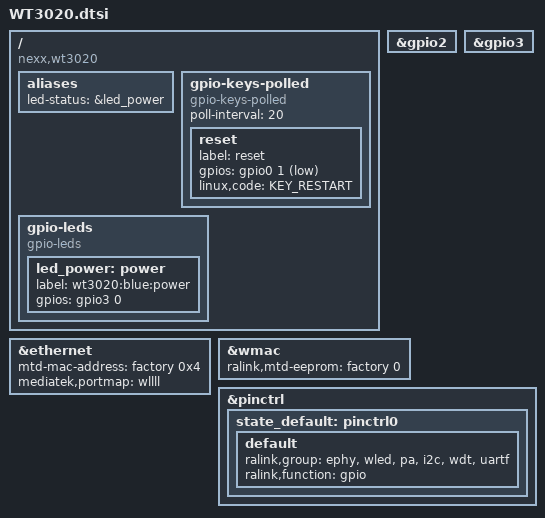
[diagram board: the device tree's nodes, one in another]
#include "mt7620n.dtsi"

#include <dt-bindings/gpio/gpio.h>
#include <dt-bindings/input/input.h>

/ {
	compatible = "nexx,wt3020", "ralink,mt7620n-soc";

	aliases {
		led-status = &led_power;
	};

	gpio-keys-polled {
		compatible = "gpio-keys-polled";
		poll-interval = <20>;

		reset {
			label = "reset";
			gpios = <&gpio0 1 GPIO_ACTIVE_LOW>;
			linux,code = <KEY_RESTART>;
		};
	};

	gpio-leds {
		compatible = "gpio-leds";

		led_power: power {
			label = "wt3020:blue:power";
			gpios = <&gpio3 0 GPIO_ACTIVE_HIGH>;
		};
	};
};

&gpio2 {
	status = "okay";
};

&gpio3 {
	status = "okay";
};

&ethernet {
	mtd-mac-address = <&factory 0x4>;
	mediatek,portmap = "wllll";
};

&wmac {
	ralink,mtd-eeprom = <&factory 0>;
};

&pinctrl {
	state_default: pinctrl0 {
		default {
			ralink,group = "ephy", "wled", "pa", "i2c", "wdt", "uartf";
			ralink,function = "gpio";
		};
	};
};
